# LargeDummyDevice register map
File version: 1.0
Registers are 32-bit, read-write, no defined reset value unless marked. A register's access mark holds for its fields unless they carry their own. Offsets are from the block's base; [hi:lo] are bit positions.

## PERIPHERAL_17
Base 0x40010000
0x04 REG_1 — Register 1
  [33:30] FIELD_1
0x08 REG_2 — Register 2
  [35:31] FIELD_1, [31] FIELD_4, [32:30] FIELD_22, [33:29] FIELD_20, [30:28] FIELD_2, [31:28] FIELD_11, [28:27] FIELD_12, [29:25] FIELD_8, [21] FIELD_3, [22:20] FIELD_5, [22:18] FIELD_13, [18:17] FIELD_10, [19:15] FIELD_15, [13:9] FIELD_6, [13:9] FIELD_16, [10:8] FIELD_18, [11:8] FIELD_25, [9:7] FIELD_9, [5:4] FIELD_23, [3] FIELD_17, [7:3] FIELD_24, [1:0] FIELD_7, [3:0] FIELD_14, [2:0] FIELD_19, [0] FIELD_21
0x0C REG_3 — Register 3
  [31:27] FIELD_5, [27:26] FIELD_14, [26:22] FIELD_7, [22:20] FIELD_11, [20:18] FIELD_1, [12:11] FIELD_9, [10:9] FIELD_10, [10:9] FIELD_15, [10:8] FIELD_6, [4] FIELD_2, [7:4] FIELD_4, [3] FIELD_3, [7:3] FIELD_8, [1] FIELD_13, [2:0] FIELD_12
0x10 REG_4 — Register 4
  [26] FIELD_5, [24:21] FIELD_3, [21:20] FIELD_2, [12:9] FIELD_4, [4] FIELD_1
0x14 REG_5 — Register 5
  [27:25] FIELD_3, [24:22] FIELD_9, [23:20] FIELD_2, [19:18] FIELD_1, [18] FIELD_4, [19:16] FIELD_5, [17:16] FIELD_10, [14] FIELD_7, [12:11] FIELD_8, [0] FIELD_6
0x18 REG_6 — Register 6
  [31:30] FIELD_9, [29:27] FIELD_10, [23] FIELD_1, [25:23] FIELD_6, [24:22] FIELD_11, [22:20] FIELD_12, [16:15] FIELD_3, [16:14] FIELD_5, [17:14] FIELD_8, [15:12] FIELD_2, [14:10] FIELD_13, [7:4] FIELD_4, [4:3] FIELD_7
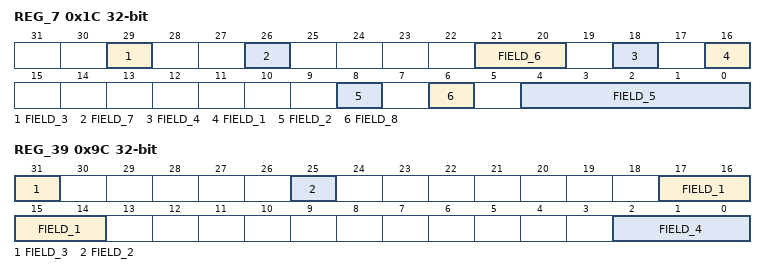
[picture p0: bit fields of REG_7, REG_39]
0x1C REG_7 — Register 7
  [29] FIELD_3, [26] FIELD_7, [21:20] FIELD_6, [18] FIELD_4, [16] FIELD_1, [8] FIELD_2, [6] FIELD_8, [4:0] FIELD_5
0x20 REG_8 — Register 8
  [34:31] FIELD_1, [35:31] FIELD_19, [29] FIELD_2, [29:27] FIELD_16, [27:26] FIELD_26, [27:25] FIELD_3, [27:24] FIELD_21, [25:22] FIELD_6, [26:22] FIELD_10, [25:21] FIELD_31, [24:20] FIELD_9, [21:20] FIELD_13, [22:18] FIELD_24, [20:16] FIELD_18, [19:16] FIELD_20, [14] FIELD_12, [15:14] FIELD_23, [13] FIELD_22, [16:12] FIELD_25, [14:11] FIELD_7, [11] FIELD_11, [13:11] FIELD_14, [9] FIELD_8, [12:9] FIELD_27, [9:8] FIELD_28, [10:7] FIELD_15, [8:7] FIELD_17, [9:7] FIELD_29, [7:5] FIELD_30, [7:3] FIELD_4, [5:3] FIELD_5
0x24 REG_9 — Register 9
  [26:23] FIELD_1
0x28 REG_10 — Register 10
  [33:29] FIELD_10, [28] FIELD_13, [30:27] FIELD_5, [27] FIELD_14, [27:26] FIELD_22, [28:25] FIELD_2, [27:24] FIELD_1, [22:21] FIELD_12, [22:20] FIELD_21, [21:18] FIELD_4, [20:17] FIELD_3, [19:16] FIELD_18, [18:15] FIELD_7, [13:11] FIELD_15, [13:10] FIELD_9, [13:10] FIELD_19, [7] FIELD_17, [8:6] FIELD_6, [8:5] FIELD_8, [2] FIELD_20, [2:1] FIELD_11, [4:1] FIELD_16
0x2C REG_11 — Register 11
  [32:31] FIELD_1, [34:31] FIELD_12, [21:20] FIELD_4, [20:18] FIELD_8, [19:17] FIELD_11, [18:16] FIELD_3, [15:11] FIELD_7, [9] FIELD_5, [12:8] FIELD_2, [8] FIELD_9, [8:7] FIELD_6, [6] FIELD_10
0x30 REG_12 — Register 12
  [34:31] FIELD_6, [30] FIELD_4, [32:30] FIELD_9, [28] FIELD_13, [30:27] FIELD_3, [29:27] FIELD_20, [23:20] FIELD_2, [21:19] FIELD_11, [19] FIELD_21, [20:16] FIELD_16, [19:15] FIELD_19, [16:14] FIELD_12, [17:13] FIELD_1, [13:12] FIELD_23, [16:12] FIELD_24, [11:8] FIELD_22, [6:5] FIELD_7, [9:5] FIELD_8, [5:3] FIELD_14, [7:3] FIELD_15, [1] FIELD_5, [4:1] FIELD_10, [5:1] FIELD_18, [4:0] FIELD_17
0x34 REG_13 — Register 13
  [34:30] FIELD_22, [33:29] FIELD_20, [29:28] FIELD_2, [32:28] FIELD_5, [27:26] FIELD_19, [27:25] FIELD_8, [27:23] FIELD_11, [22] FIELD_9, [26:22] FIELD_18, [23:21] FIELD_1, [24:20] FIELD_13, [22:19] FIELD_4, [20:19] FIELD_16, [19:18] FIELD_3, [18] FIELD_17, [19:16] FIELD_6, [20:16] FIELD_10, [16:15] FIELD_14, [15] FIELD_23, [4] FIELD_21, [5:3] FIELD_7, [2] FIELD_24, [3:0] FIELD_12, [0] FIELD_15
0x38 REG_14 — Register 14
  [34:31] FIELD_4, [33:31] FIELD_30, [33:30] FIELD_1, [34:30] FIELD_21, [33:29] FIELD_26, [28:26] FIELD_23, [24:23] FIELD_5, [27:23] FIELD_14, [22:21] FIELD_29, [24:20] FIELD_31, [18] FIELD_20, [18:17] FIELD_9, [19:17] FIELD_28, [16:15] FIELD_8, [19:15] FIELD_10, [14:12] FIELD_15, [14:11] FIELD_13, [12:10] FIELD_3, [10] FIELD_19, [10:9] FIELD_16, [11:8] FIELD_12, [11:8] FIELD_22, [6] FIELD_7, [7:6] FIELD_18, [9:5] FIELD_2, [4] FIELD_11, [4] FIELD_25, [6:2] FIELD_6, [5:2] FIELD_17, [2:1] FIELD_24, [1:0] FIELD_27
0x3C REG_15 — Register 15
  [23:19] FIELD_1, [19:17] FIELD_2
0x40 REG_16 — Register 16
  [29] FIELD_6, [33:29] FIELD_14, [28] FIELD_12, [29:27] FIELD_10, [28:27] FIELD_16, [28:26] FIELD_15, [27:25] FIELD_18, [24:23] FIELD_2, [20:18] FIELD_7, [22:18] FIELD_13, [17:15] FIELD_9, [11] FIELD_1, [12:11] FIELD_4, [14:11] FIELD_17, [14:10] FIELD_11, [5] FIELD_5, [7:3] FIELD_8, [5:2] FIELD_3
0x44 REG_17 — Register 17
  [31:28] FIELD_6, [29:27] FIELD_5, [29:26] FIELD_2, [25] FIELD_7, [29:25] FIELD_15, [27:24] FIELD_3, [23:21] FIELD_9, [19] FIELD_14, [18] FIELD_11, [18:15] FIELD_1, [15:13] FIELD_4, [16:13] FIELD_12, [14:12] FIELD_8, [10:6] FIELD_10, [7:5] FIELD_13
0x48 REG_18 — Register 18
  [30:27] FIELD_2, [26:25] FIELD_1, [24] FIELD_5, [20] FIELD_7, [22:19] FIELD_4, [19] FIELD_8, [20:16] FIELD_10, [14:12] FIELD_6, [8] FIELD_3, [4:3] FIELD_9
0x4C REG_19 — Register 19
  [32:31] FIELD_4, [30] FIELD_5, [30] FIELD_11, [32:30] FIELD_22, [26] FIELD_3, [29:25] FIELD_21, [25:23] FIELD_16, [22] FIELD_23, [21:20] FIELD_7, [20:16] FIELD_9, [16:14] FIELD_24, [17:13] FIELD_1, [16:13] FIELD_2, [17:13] FIELD_13, [16:13] FIELD_15, [16:13] FIELD_19, [11:9] FIELD_17, [7] FIELD_18, [7:6] FIELD_20, [6:5] FIELD_8, [7:4] FIELD_10, [7:3] FIELD_12, [3] FIELD_14, [5:3] FIELD_25, [5:1] FIELD_6
0x50 REG_20 — Register 20
  [31] FIELD_26, [33:31] FIELD_27, [32:29] FIELD_17, [28] FIELD_4, [27] FIELD_3, [28:27] FIELD_15, [27:26] FIELD_1, [28:25] FIELD_25, [29:25] FIELD_31, [27:24] FIELD_12, [23:22] FIELD_16, [25:21] FIELD_10, [21:19] FIELD_9, [18] FIELD_7, [17] FIELD_11, [18:17] FIELD_23, [15] FIELD_2, [18:15] FIELD_14, [16:13] FIELD_20, [17:13] FIELD_24, [13:11] FIELD_29, [13:10] FIELD_6, [13:10] FIELD_30, [9:8] FIELD_13, [11:7] FIELD_8, [7] FIELD_21, [9:7] FIELD_22, [10:6] FIELD_18, [2] FIELD_28, [2] FIELD_32, [5:1] FIELD_5, [2:0] FIELD_19
0x54 REG_21 — Register 21
  [34:31] FIELD_1, [32:29] FIELD_4, [31:28] FIELD_10, [27] FIELD_13, [27:24] FIELD_5, [22:21] FIELD_6, [20:17] FIELD_14, [18:14] FIELD_12, [11:10] FIELD_8, [12:10] FIELD_11, [7:6] FIELD_2, [8:5] FIELD_7, [5:3] FIELD_9, [2] FIELD_3
0x58 REG_22 — Register 22
  [35:31] FIELD_12, [35:31] FIELD_30, [33:29] FIELD_15, [29:27] FIELD_23, [26] FIELD_9, [30:26] FIELD_13, [27:26] FIELD_25, [26:25] FIELD_6, [29:25] FIELD_24, [28:24] FIELD_7, [25:24] FIELD_8, [24] FIELD_19, [24] FIELD_22, [27:23] FIELD_16, [25:22] FIELD_3, [25:21] FIELD_14, [19] FIELD_2, [20:17] FIELD_17, [21:17] FIELD_29, [20:16] FIELD_10, [11:8] FIELD_18, [11:8] FIELD_21, [7] FIELD_28, [9:6] FIELD_5, [10:6] FIELD_27, [4] FIELD_4, [3:2] FIELD_1, [5:2] FIELD_11, [3:2] FIELD_20, [1:0] FIELD_26
0x5C REG_23 — Register 23
  [33:30] FIELD_2, [30] FIELD_15, [29] FIELD_7, [30:29] FIELD_11, [31:27] FIELD_13, [27:26] FIELD_5, [21:20] FIELD_1, [16:12] FIELD_10, [16:12] FIELD_14, [10] FIELD_8, [12:9] FIELD_9, [8] FIELD_6, [6:4] FIELD_12, [4:2] FIELD_3, [4:1] FIELD_4
0x60 REG_24 — Register 24
  [33:30] FIELD_9, [32:30] FIELD_12, [31:28] FIELD_18, [30:27] FIELD_21, [27:26] FIELD_4, [28:24] FIELD_20, [27:23] FIELD_7, [23] FIELD_17, [21] FIELD_28, [20:18] FIELD_1, [22:18] FIELD_14, [17] FIELD_2, [20:17] FIELD_5, [14] FIELD_15, [16:12] FIELD_26, [15:11] FIELD_27, [11:10] FIELD_8, [8:7] FIELD_11, [10:7] FIELD_19, [10:7] FIELD_25, [8:6] FIELD_13, [8:6] FIELD_23, [5] FIELD_22, [5:3] FIELD_10, [3:1] FIELD_6, [3:1] FIELD_24, [2:0] FIELD_3, [2:0] FIELD_16
0x64 REG_25 — Register 25
  [32:30] FIELD_15, [33:29] FIELD_16, [31:28] FIELD_12, [29:27] FIELD_11, [25:21] FIELD_7, [21:20] FIELD_3, [21:20] FIELD_4, [15] FIELD_8, [19:15] FIELD_13, [14:12] FIELD_1, [15:11] FIELD_2, [11:9] FIELD_9, [9:8] FIELD_6, [11:7] FIELD_5, [9:6] FIELD_10, [6:5] FIELD_14, [3:1] FIELD_17
0x68 REG_26 — Register 26
  [31:30] FIELD_2, [30:27] FIELD_4, [19] FIELD_3, [19:18] FIELD_1
0x6C REG_27 — Register 27
  [31:30] FIELD_24, [34:30] FIELD_27, [32:29] FIELD_20, [27] FIELD_6, [26] FIELD_26, [29:25] FIELD_16, [25] FIELD_28, [27:24] FIELD_18, [26:22] FIELD_4, [23:22] FIELD_15, [22:21] FIELD_13, [21:20] FIELD_2, [21:19] FIELD_19, [19:17] FIELD_21, [16] FIELD_11, [17:14] FIELD_3, [13] FIELD_22, [13:11] FIELD_1, [14:11] FIELD_9, [13:10] FIELD_14, [14:10] FIELD_23, [10:7] FIELD_7, [5:4] FIELD_8, [6:2] FIELD_10, [5:2] FIELD_12, [5:1] FIELD_5, [1:0] FIELD_17, [3:0] FIELD_25
0x70 REG_28 — Register 28
  [35:31] FIELD_6, [29] FIELD_4, [31:29] FIELD_18, [29:28] FIELD_15, [30:27] FIELD_10, [28:27] FIELD_11, [30:27] FIELD_17, [28:27] FIELD_19, [28:24] FIELD_9, [26:24] FIELD_21, [19] FIELD_2, [17] FIELD_3, [19:15] FIELD_16, [18:14] FIELD_1, [14] FIELD_14, [12:10] FIELD_12, [9:8] FIELD_5, [11:8] FIELD_7, [7:5] FIELD_20, [5:4] FIELD_13, [4:0] FIELD_8
0x74 REG_29 — Register 29
  [27] FIELD_7, [29:25] FIELD_5, [25:23] FIELD_2, [26:23] FIELD_6, [21:18] FIELD_8, [14:12] FIELD_3, [9] FIELD_1, [2:0] FIELD_4
0x78 REG_30 — Register 30
  [35:31] FIELD_7, [31:30] FIELD_17, [32:30] FIELD_21, [34:30] FIELD_23, [30:29] FIELD_22, [28] FIELD_1, [30:28] FIELD_28, [28:27] FIELD_11, [31:27] FIELD_29, [27:25] FIELD_8, [23] FIELD_32, [24:21] FIELD_18, [23:20] FIELD_9, [21:20] FIELD_20, [22:19] FIELD_25, [17] FIELD_16, [20:17] FIELD_19, [20:16] FIELD_2, [18:15] FIELD_6, [15:14] FIELD_4, [14:13] FIELD_3, [13:12] FIELD_14, [13:12] FIELD_27, [11] FIELD_12, [13:11] FIELD_13, [13:11] FIELD_24, [10] FIELD_5, [8:6] FIELD_10, [8:6] FIELD_30, [7:4] FIELD_15, [6:4] FIELD_26, [4:0] FIELD_31
0x7C REG_31 — Register 31
  [33:31] FIELD_7, [33:29] FIELD_19, [31:29] FIELD_20, [32:28] FIELD_11, [30:27] FIELD_2, [28:26] FIELD_1, [26:25] FIELD_17, [26:23] FIELD_18, [23:19] FIELD_15, [19:15] FIELD_13, [14] FIELD_4, [13:10] FIELD_6, [10] FIELD_10, [12:9] FIELD_12, [10:9] FIELD_14, [9:6] FIELD_5, [6] FIELD_9, [4:3] FIELD_16, [3:1] FIELD_3, [3:1] FIELD_8
0x80 REG_32 — Register 32
  [31] FIELD_7, [30:29] FIELD_13, [30:27] FIELD_12, [29:26] FIELD_4, [27:25] FIELD_18, [19] FIELD_15, [20:18] FIELD_3, [19:17] FIELD_14, [16:14] FIELD_2, [15:14] FIELD_9, [12:11] FIELD_16, [12:10] FIELD_11, [9] FIELD_5, [11:7] FIELD_8, [7:4] FIELD_1, [6:3] FIELD_6, [2:1] FIELD_17, [0] FIELD_10
0x84 REG_33 — Register 33
  [30:26] FIELD_4, [28:26] FIELD_13, [27:25] FIELD_5, [25] FIELD_15, [22:20] FIELD_7, [23:20] FIELD_16, [19:18] FIELD_11, [20:16] FIELD_6, [16:15] FIELD_3, [14] FIELD_2, [17:13] FIELD_8, [16:13] FIELD_12, [12:8] FIELD_18, [9:8] FIELD_21, [7] FIELD_17, [11:7] FIELD_19, [6] FIELD_14, [8:4] FIELD_10, [5:3] FIELD_9, [2] FIELD_20, [1] FIELD_1, [1:0] FIELD_22
0x88 REG_34 — Register 34
  [26:22] FIELD_2, [22:21] FIELD_4, [20:19] FIELD_5, [19:18] FIELD_3, [15:11] FIELD_1
0x8C REG_35 — Register 35
  [27:26] FIELD_4, [21] FIELD_2, [10] FIELD_1, [8] FIELD_3, [2:1] FIELD_5, [5:1] FIELD_6
0x90 REG_36 — Register 36
  [30] FIELD_1, [31:29] FIELD_2, [30:29] FIELD_3, [31:29] FIELD_19, [29:28] FIELD_9, [27] FIELD_15, [27:25] FIELD_6, [29:25] FIELD_12, [24] FIELD_8, [24] FIELD_13, [26:24] FIELD_17, [26:22] FIELD_4, [23:21] FIELD_22, [24:20] FIELD_14, [15] FIELD_5, [16:12] FIELD_11, [13:10] FIELD_16, [13:9] FIELD_10, [7] FIELD_18, [6:5] FIELD_7, [6:4] FIELD_21, [2:0] FIELD_20, [2:0] FIELD_23
0x94 REG_37 — Register 37
  [34:30] FIELD_3, [22:19] FIELD_6, [21:19] FIELD_7, [18:14] FIELD_5, [8] FIELD_1, [11:7] FIELD_4, [5] FIELD_2
0x98 REG_38 — Register 38
  [31:28] FIELD_8, [32:28] FIELD_17, [24:22] FIELD_4, [24:22] FIELD_24, [22] FIELD_25, [22:20] FIELD_10, [21:19] FIELD_1, [22:19] FIELD_2, [23:19] FIELD_12, [23:19] FIELD_20, [16:15] FIELD_13, [18:14] FIELD_19, [13] FIELD_18, [14:13] FIELD_22, [12] FIELD_21, [11] FIELD_9, [10] FIELD_7, [14:10] FIELD_11, [7] FIELD_6, [6] FIELD_3, [7:4] FIELD_16, [5:3] FIELD_14, [3:2] FIELD_5, [3:1] FIELD_15, [4:1] FIELD_23
0x9C REG_39 — Register 39
  [31] FIELD_3, [25] FIELD_2, [17:14] FIELD_1, [2:0] FIELD_4
0xA0 REG_40 — Register 40
  [30] FIELD_10, [25:23] FIELD_13, [23:21] FIELD_1, [21:19] FIELD_3, [20:19] FIELD_11, [16] FIELD_6, [15:14] FIELD_8, [17:14] FIELD_9, [14:13] FIELD_2, [14:12] FIELD_4, [14:12] FIELD_12, [6:3] FIELD_7, [2:0] FIELD_5
0xA4 REG_41 — Register 41
  [35:31] FIELD_17, [29:28] FIELD_4, [30:28] FIELD_8, [29:25] FIELD_16, [26:24] FIELD_2, [27:24] FIELD_5, [24:23] FIELD_3, [20:18] FIELD_14, [18:15] FIELD_10, [17:15] FIELD_13, [17:14] FIELD_9, [14:12] FIELD_7, [14:11] FIELD_15, [8:5] FIELD_12, [7:4] FIELD_11, [2:0] FIELD_1, [4:0] FIELD_6
0xA8 REG_42 — Register 42
  [32:31] FIELD_3, [31:30] FIELD_12, [34:30] FIELD_16, [31:30] FIELD_20, [33:30] FIELD_21, [30:28] FIELD_18, [28:26] FIELD_8, [30:26] FIELD_22, [29:25] FIELD_7, [25] FIELD_10, [26:24] FIELD_11, [26:23] FIELD_26, [24:22] FIELD_14, [22:21] FIELD_28, [22:20] FIELD_13, [22:18] FIELD_5, [20:17] FIELD_17, [20:17] FIELD_24, [18:16] FIELD_15, [20:16] FIELD_25, [17:15] FIELD_9, [12] FIELD_6, [15:12] FIELD_23, [14:11] FIELD_4, [15:11] FIELD_27, [7] FIELD_1, [8:4] FIELD_2, [4:0] FIELD_19
0xAC REG_43 — Register 43
  [29] FIELD_6, [32:29] FIELD_8, [29:27] FIELD_1, [26] FIELD_3, [29:26] FIELD_14, [26:25] FIELD_5, [26:25] FIELD_15, [26:24] FIELD_7, [25:24] FIELD_19, [26:23] FIELD_9, [24:23] FIELD_18, [22:19] FIELD_12, [18:16] FIELD_20, [18:14] FIELD_13, [14] FIELD_21, [13:12] FIELD_10, [10] FIELD_2, [10:9] FIELD_4, [10:7] FIELD_17, [7:4] FIELD_11, [5:3] FIELD_16
0xB0 REG_44 — Register 44
  [32:30] FIELD_11, [32:28] FIELD_7, [32:28] FIELD_9, [29:27] FIELD_12, [24:22] FIELD_4, [21:20] FIELD_8, [19] FIELD_3, [20:17] FIELD_14, [18:16] FIELD_13, [15:11] FIELD_2, [9:7] FIELD_1, [11:7] FIELD_5, [8:6] FIELD_10, [7:3] FIELD_6
0xB4 REG_45 — Register 45
  [35:31] FIELD_24, [30:29] FIELD_17, [31:27] FIELD_18, [31:27] FIELD_23, [30:26] FIELD_10, [27:26] FIELD_12, [25:24] FIELD_7, [27:24] FIELD_20, [26:23] FIELD_15, [24:23] FIELD_22, [20] FIELD_8, [20:19] FIELD_19, [16] FIELD_9, [20:16] FIELD_21, [17:14] FIELD_2, [17:14] FIELD_27, [16:13] FIELD_16, [16:12] FIELD_26, [12:11] FIELD_25, [13:10] FIELD_1, [11:9] FIELD_3, [9] FIELD_11, [9:7] FIELD_14, [6:5] FIELD_6, [6:4] FIELD_4, [4:3] FIELD_13, [4:2] FIELD_5
